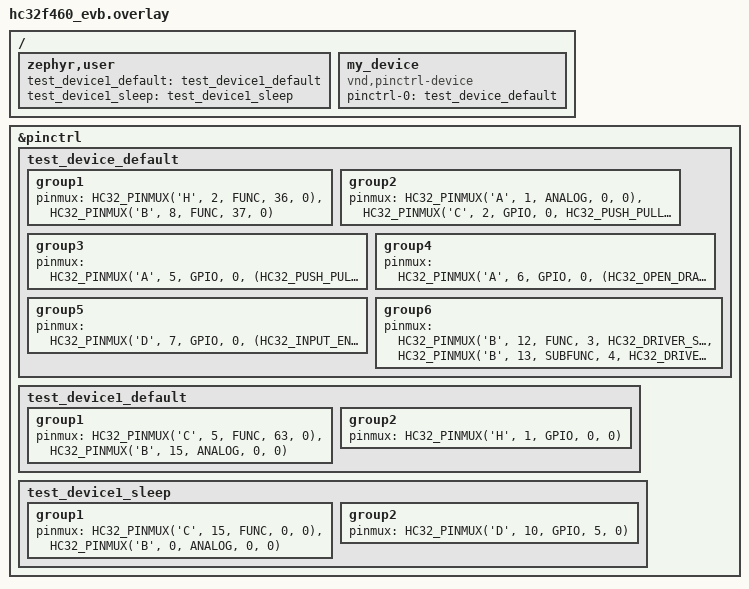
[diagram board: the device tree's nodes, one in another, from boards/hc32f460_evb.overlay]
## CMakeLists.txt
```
# Copyright (c) 2021 Teslabs Engineering S.L.
# SPDX-License-Identifier: Apache-2.0

cmake_minimum_required(VERSION 3.20.0)
find_package(Zephyr REQUIRED HINTS $ENV{ZEPHYR_BASE})

project(pinctrl_hc32)

target_sources(app PRIVATE ../common/test_device.c)
target_sources(app PRIVATE src/main.c)
```

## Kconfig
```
# Copyright (c) 2021 Teslabs Engineering S.L.
# SPDX-License-Identifier: Apache-2.0

mainmenu "pinctrl HC32 DT Test"

source "Kconfig.zephyr"

config PINCTRL_TEST_NON_STATIC
	bool "Access to pin control configuration"
	select PINCTRL_NON_STATIC
	help
	  This option should be selected by unit tests that need to access the pin
	  control configuration defined in a device driver.
```

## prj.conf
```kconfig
# Copyright (c) 2021 Teslabs Engineering S.L.
# SPDX-License-Identifier: Apache-2.0

CONFIG_ZTEST=y
CONFIG_ZTEST_NEW_API=y
CONFIG_PINCTRL=y

CONFIG_UART_CONSOLE=y
CONFIG_RTT_CONSOLE=y
CONFIG_USE_SEGGER_RTT=y

CONFIG_NO_OPTIMIZATIONS=y

CONFIG_PINCTRL_TEST_NON_STATIC=y

CONFIG_PINCTRL_DYNAMIC=y
```

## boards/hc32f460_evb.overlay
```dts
/*
 * Copyright (c) 2021 Teslabs Engineering S.L.
 * SPDX-License-Identifier: Apache-2.0
 */

/ {
	zephyr,user {
		test_device1_default = <&test_device1_default>;
		test_device1_sleep = <&test_device1_sleep>;
	};

	my_device: my_device {
		compatible = "vnd,pinctrl-device";
		pinctrl-0 = <&test_device_default>;
		pinctrl-names = "default";
		status = "okay";
	};
};

&pinctrl {
	test_device_default: test_device_default {
		/* Note: the groups are just meant for testing if properties and
		   pins are parsed correctly, but do not necessarily represent a
		   feasible combination */
		group1 {
			pinmux = <HC32_PINMUX('H', 2, FUNC, 36, 0)>,
				 <HC32_PINMUX('B', 8, FUNC, 37, 0)>;
		};
		group2 {
			pinmux = <HC32_PINMUX('A', 1, ANALOG, 0, 0)>,
				 <HC32_PINMUX('C', 2, GPIO, 0, HC32_PUSH_PULL |HC32_OUTPUT_ENABLE | HC32_OUTPUT_HIGH | HC32_DRIVER_STRENGTH_HIGH)>;
		};
		group3 {
			pinmux = <HC32_PINMUX('A', 5, GPIO, 0, (HC32_PUSH_PULL |HC32_OUTPUT_ENABLE | HC32_OUTPUT_HIGH | HC32_DRIVER_STRENGTH_HIGH))>;
		};

		group4 {
			pinmux = <HC32_PINMUX('A', 6, GPIO, 0, (HC32_OPEN_DRAIN| HC32_OUTPUT_ENABLE| HC32_OUTPUT_LOW))>;
		};

		group5 {
			pinmux = <HC32_PINMUX('D', 7, GPIO, 0, (HC32_INPUT_ENABLE |HC32_PULL_UP| HC32_INVERT_ENABLE| HC32_CINSEL_CMOS))>;
		};

		group6 {
			pinmux = <HC32_PINMUX('B', 12, FUNC, 3, HC32_DRIVER_STRENGTH_MEDIUM)>,
			         <HC32_PINMUX('B', 13, SUBFUNC, 4, HC32_DRIVER_STRENGTH_HIGH)>;
		};
	};

	test_device1_default: test_device1_default {
		/* Note: the groups are just meant for testing if properties and
		   pins are parsed correctly, but do not necessarily represent a
		   feasible combination */
		group1 {
			pinmux = <HC32_PINMUX('C', 5, FUNC, 63, 0)>,
				 <HC32_PINMUX('B', 15, ANALOG, 0, 0)>;
		};
		group2 {
			pinmux = <HC32_PINMUX('H', 1, GPIO, 0, 0)>;
		};
	};

	test_device1_sleep: test_device1_sleep {
		/* Note: the groups are just meant for testing if properties and
		   pins are parsed correctly, but do not necessarily represent a
		   feasible combination */
		group1 {
			pinmux = <HC32_PINMUX('C', 15, FUNC, 0, 0)>,
				 <HC32_PINMUX('B', 0, ANALOG, 0, 0)>;
		};
		group2 {
			pinmux = <HC32_PINMUX('D', 10, GPIO, 5, 0)>;
		};
	};
};
```

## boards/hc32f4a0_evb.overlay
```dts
/*
 * Copyright (c) 2021 Teslabs Engineering S.L.
 * SPDX-License-Identifier: Apache-2.0
 */

/ {
	zephyr,user {
		test_device1_default = <&test_device1_default>;
		test_device1_sleep = <&test_device1_sleep>;
	};

	my_device: my_device {
		compatible = "vnd,pinctrl-device";
		pinctrl-0 = <&test_device_default>;
		pinctrl-names = "default";
		status = "okay";
	};
};

&pinctrl {
	test_device_default: test_device_default {
		/* Note: the groups are just meant for testing if properties and
		pins are parsed correctly, but do not necessarily represent a
		feasible combination */
		group1 {
			pinmux = <HC32_PINMUX('H', 2, FUNC, 36, 0)>,
			         <HC32_PINMUX('B', 8, FUNC, 37, 0)>;
		};
		group2 {
			pinmux = <HC32_PINMUX('A', 1, ANALOG, 0, 0)>,
			         <HC32_PINMUX('C', 2, GPIO, 0, 0)>;
		};
		group3 {
			pinmux = <HC32_PINMUX('A', 5, GPIO, 0, (HC32_PUSH_PULL |HC32_OUTPUT_ENABLE | HC32_OUTPUT_HIGH | HC32_DRIVER_STRENGTH_HIGH))>;
		};

		group4 {
			pinmux = <HC32_PINMUX('A', 6, GPIO, 0, (HC32_OPEN_DRAIN| HC32_OUTPUT_ENABLE| HC32_OUTPUT_LOW))>;
		};

		group5 {
			pinmux = <HC32_PINMUX('D', 7, GPIO, 0, (HC32_INPUT_ENABLE |HC32_PULL_UP| HC32_INVERT_ENABLE| HC32_CINSEL_CMOS))>;
		};

		group6 {
			pinmux = <HC32_PINMUX('B', 12, FUNC, 3, HC32_DRIVER_STRENGTH_MEDIUM)>,
			         <HC32_PINMUX('B', 13, SUBFUNC, 4, HC32_DRIVER_STRENGTH_HIGH)>;
		};
	};

	test_device1_default: test_device1_default {
		/* Note: the groups are just meant for testing if properties and
		pins are parsed correctly, but do not necessarily represent a
		feasible combination */
		group1 {
			pinmux = <HC32_PINMUX('C', 5, FUNC, 63, 0)>,
			         <HC32_PINMUX('B', 15, ANALOG, 0, 0)>;
		};
		group2 {
			pinmux = <HC32_PINMUX('H', 1, GPIO, 0, 0)>;
		};
	};

	test_device1_sleep: test_device1_sleep {
		/* Note: the groups are just meant for testing if properties and
		pins are parsed correctly, but do not necessarily represent a
		feasible combination */
		group1 {
			pinmux = <HC32_PINMUX('C', 15, FUNC, 0, 0)>,
			         <HC32_PINMUX('B', 0, ANALOG, 0, 0)>;
		};
		group2 {
			pinmux = <HC32_PINMUX('D', 10, GPIO, 5, 0)>;
		};
	};
};
```

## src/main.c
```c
/*
 * Copyright (c) 2021 Teslabs Engineering S.L.
 * SPDX-License-Identifier: Apache-2.0
 */

#include <zephyr/drivers/pinctrl.h>
#include <zephyr/ztest.h>

/* pin configuration for test device */
#define TEST_DEVICE DT_NODELABEL(my_device)
PINCTRL_DT_DEV_CONFIG_DECLARE(TEST_DEVICE);
static struct pinctrl_dev_config *pcfg = PINCTRL_DT_DEV_CONFIG_GET(TEST_DEVICE);

ZTEST(pinctrl_hc32, test_dt_extract)
{
	const struct pinctrl_state *scfg;
	pinctrl_soc_pin_t pin;

	zassert_equal(pcfg->state_cnt, 1U);

	scfg = &pcfg->states[0];

	zassert_equal(scfg->id, PINCTRL_STATE_DEFAULT);
	zassert_equal(scfg->pin_cnt, 9U);

	pin = scfg->pins[1];
	zassert_equal(HC32_PORT(pin), 1);
	zassert_equal(HC32_PIN(pin), 8);
	zassert_equal(HC32_MODE(pin), HC32_FUNC);
	zassert_equal(HC32_FUNC_NUM(pin), 37);
	zassert_equal(HC32_PIN_BIAS(pin), HC32_NO_PULL);

	pin = scfg->pins[2];
	zassert_equal(HC32_PORT(pin), 0);
	zassert_equal(HC32_PIN(pin), 1);
	zassert_equal(HC32_MODE(pin), HC32_ANALOG);

	pin = scfg->pins[4];
	zassert_equal(HC32_PIN_DRIVER_STRENGTH(pin), HC32_DRIVER_STRENGTH_HIGH);

	pin = scfg->pins[6];
	zassert_equal(HC32_CINSEL(pin), HC32_CINSEL_CMOS);

}

ZTEST(pinctrl_hc32, test_lookup_state)
{
	int ret;
	const struct pinctrl_state *scfg;

	ret = pinctrl_lookup_state(pcfg, PINCTRL_STATE_DEFAULT, &scfg);
	zassert_equal(ret, 0);
	zassert_equal_ptr(scfg, &pcfg->states[0], NULL);
}

/**
 * @brief Test that pinctrl_apply_state() works as expected.
 */
ZTEST(pinctrl_hc32, test_apply_state)
{
	zassert_ok(pinctrl_apply_state(pcfg, PINCTRL_STATE_DEFAULT));
}

PINCTRL_DT_STATE_PINS_DEFINE(DT_PATH(zephyr_user), test_device1_default);
PINCTRL_DT_STATE_PINS_DEFINE(DT_PATH(zephyr_user), test_device1_sleep);
/** Test device alternative states. */
static const struct pinctrl_state test_device_alt[] = {
	PINCTRL_DT_STATE_INIT(test_device1_default, PINCTRL_STATE_DEFAULT),
};


static const struct pinctrl_state test_device_alt_invalid[] = {
	PINCTRL_DT_STATE_INIT(test_device1_default, PINCTRL_STATE_DEFAULT),
	/* sleep state is skipped (no CONFIG_PM_DEVICE), so it is invalid */
	PINCTRL_DT_STATE_INIT(test_device1_sleep, PINCTRL_STATE_SLEEP),
};

ZTEST(pinctrl_hc32, test_update_states)
{
	int ret;
	const struct pinctrl_state *scfg;
	pinctrl_soc_pin_t pin;

	ret = pinctrl_update_states(pcfg, test_device_alt, ARRAY_SIZE(test_device_alt));
	zassert_equal(ret, 0);

	scfg = &pcfg->states[0];
	pin = scfg->pins[0];
	zassert_equal(HC32_PORT(pin), 2);
	zassert_equal(HC32_PIN(pin), 5);
	zassert_equal(HC32_MODE(pin), HC32_FUNC);
	zassert_equal(HC32_FUNC_NUM(pin), 63);
	zassert_equal(HC32_PIN_BIAS(pin), HC32_NO_PULL);

	ret = pinctrl_update_states(pcfg, test_device_alt_invalid, ARRAY_SIZE(test_device_alt_invalid));
	zassert_equal(ret, -EINVAL);
}

ZTEST_SUITE(pinctrl_hc32, NULL, NULL, NULL, NULL, NULL);
```
